# ESP32-H21 register map
Vendor: ESPRESSIF SYSTEMS (SHANGHAI) CO., LTD.; Series: ESP32 H-Series; File version: 1
CPU: RV32IMAC r0p0, little endian, no MPU, no FPU, 0 interrupt priority bits
Address unit: 32 bits
Registers are 32-bit, read-write, reset 0x0 unless marked. A register's access mark holds for its fields unless they carry their own. Offsets are from the block's base; [hi:lo] are bit positions; lines under a group give offsets from that group; {n}, {i} and the like mark numbered series.

## HMAC — HMAC (Hash-based Message Authentication Code) Accelerator
Base 0x6008D000
0x40 SET_START wo — Process control register 0.
  [0] SET_START — Start hmac operation.
0x44 SET_PARA_PURPOSE wo — Configure purpose.
  [3:0] PURPOSE_SET — Set hmac parameter purpose.
0x48 SET_PARA_KEY wo — Configure key.
  [2:0] KEY_SET — Set hmac parameter key.
0x4C SET_PARA_FINISH wo — Finish initial configuration.
  [0] SET_PARA_END — Finish hmac configuration.
0x50 SET_MESSAGE_ONE wo — Process control register 1.
  [0] SET_TEXT_ONE — Call SHA to calculate one message block.
0x54 SET_MESSAGE_ING wo — Process control register 2.
  [0] SET_TEXT_ING — Continue typical hmac.
0x58 SET_MESSAGE_END wo — Process control register 3.
  [0] SET_TEXT_END — Start hardware padding.
0x5C SET_RESULT_FINISH wo — Process control register 4.
  [0] SET_RESULT_END — After read result from upstream, then let hmac back to idle.
0x60 SET_INVALIDATE_JTAG wo — Invalidate register 0.
  [0] SET_INVALIDATE_JTAG — Clear result from hmac downstream JTAG.
0x64 SET_INVALIDATE_DS wo — Invalidate register 1.
  [0] SET_INVALIDATE_DS — Clear result from hmac downstream DS.
0x68 QUERY_ERROR ro — Error register.
  [0] QUERY_CHECK — Hmac configuration state. 0: key are agree with purpose. 1: error
0x6C QUERY_BUSY ro — Busy register.
  [0] BUSY_STATE — Hmac state. 1'b0: idle. 1'b1: busy
{0x80+4i} WR_MESSAGE_MEM[{i}] (i=0..15) access not given — Message block memory.
{0xC0+4i} RD_RESULT_MEM[{i}] (i=0..7) access not given — Result from upstream.
0xF0 SET_MESSAGE_PAD wo — Process control register 5.
  [0] SET_TEXT_PAD — Start software padding.
0xF4 ONE_BLOCK wo — Process control register 6.
  [0] SET_ONE_BLOCK — Don't have to do padding.
0xF8 SOFT_JTAG_CTRL wo — Jtag register 0.
  [0] SOFT_JTAG_CTRL — Turn on JTAG verification.
0xFC WR_JTAG wo — Jtag register 1.
  [31:0] WR_JTAG — 32-bit of key to be compared.
0x1FC DATE

## HP_APM — HP_APM Peripheral
Base 0x60099000
0x00 REGION_FILTER_EN reset 0x1 — Region filter enable register
  [15:0] REGION_FILTER_EN — Region filter enable
{0x4+0xC*i} REGION{i} (i=0..15) group — Cluster REGION{i}, containing REGION*_ADDR_START, REGION*_ADDR_END, REGION*_PMS_ATTR
  0x00 ADDR_START — Region address register
    [31:0] ADDR_START — Start address of region0
  0x04 ADDR_END reset 0xFFFFFFFF — Region address register
    [31:0] ADDR_END — End address of region0
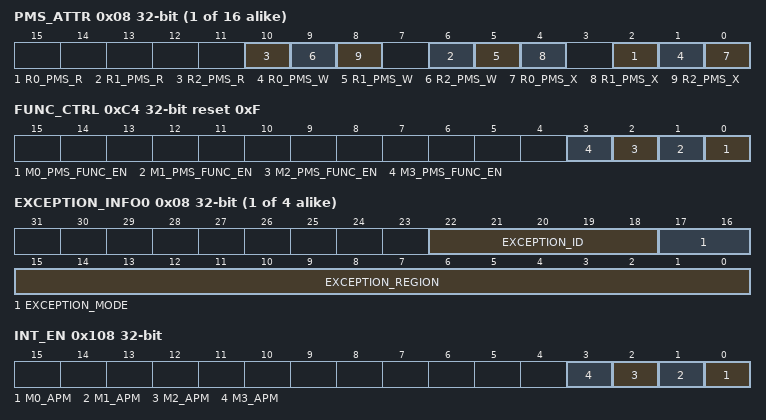
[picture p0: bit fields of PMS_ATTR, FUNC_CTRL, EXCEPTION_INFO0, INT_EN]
  0x08 PMS_ATTR — Region access authority attribute register
    [4n+2] R{n}_PMS_R (n=0..2) — Region read authority in REE_MODE{n}
    [4n+1] R{n}_PMS_W (n=0..2) — Region write authority in REE_MODE{n}
    [4n] R{n}_PMS_X (n=0..2) — Region execute authority in REE_MODE{n}
0xC4 FUNC_CTRL reset 0xF — PMS function control register
  [n] M{n}_PMS_FUNC_EN (n=0..3) — PMS M{n} function enable
{0xC8+0x10*i} M{i} (i=0..3) group — Cluster M{i}, containing M?_STATUS, M?_STATUS_CLR, M?_EXCEPTION_INFO0, M?_EXCEPTION_INFO1
  0x00 STATUS ro — M0 status register
    [1:0] EXCEPTION_STATUS
  0x04 STATUS_CLR wo — M0 status clear register
    [0] REGION_STATUS_CLR — Clear exception status
  0x08 EXCEPTION_INFO0 ro — M0 exception_info0 register
    [22:18] EXCEPTION_ID — Exception id information
    [17:16] EXCEPTION_MODE
    [15:0] EXCEPTION_REGION
  0x0C EXCEPTION_INFO1 ro — M0 exception_info1 register
    [31:0] EXCEPTION_ADDR
0x108 INT_EN — APM interrupt enable register
  [n] M{n}_APM (n=0..3) — APM M{n} interrupt enable
0x10C CLOCK_GATE reset 0x1 — clock gating register
  [0] CLK_EN — reg_clk_en
0x7FC DATE — Version register

## INTERRUPT_CORE0 — Interrupt Controller (Core 0)
Base 0x60010000
{0x0+4i} CORE_0_INTR_MAP{i} (i=0..64)
  [4:0] MAP
{0x104+4i} CORE_0_INTR_STATUS{i} (i=0..2) ro — register description
  [31:0] INT_STATUS_0 — Status register for interrupt sources 0~31 mapping register
0x110 CLOCK_GATE reset 0x1 — register description
  [0] REG_CLK_EN — Clock register
0x7FC INTERRUPT_REG_DATE — register description
